# STM32MP157 register map
File version: 1.6
CPU: CM4 r0p1, little endian, no MPU, FPU, 4 interrupt priority bits
Registers are 32-bit, read-write, reset 0x0 unless marked. A register's access mark holds for its fields unless they carry their own. Offsets are from the block's base; [hi:lo] are bit positions; {n}, {i} and the like mark numbered series.

## TZC
Base 0x5C006000
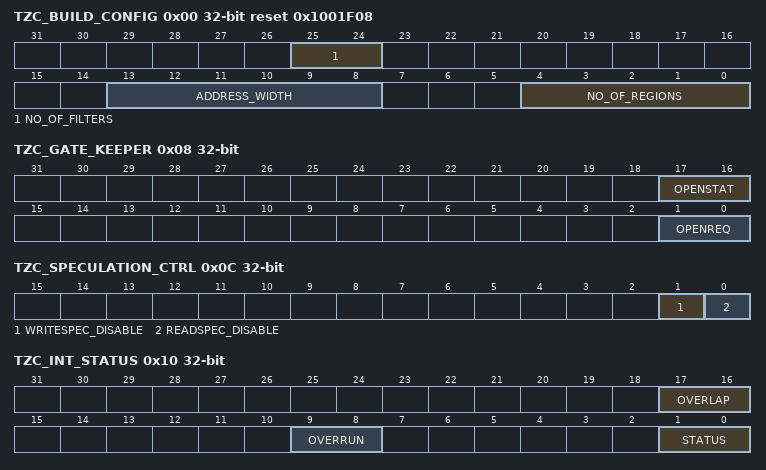
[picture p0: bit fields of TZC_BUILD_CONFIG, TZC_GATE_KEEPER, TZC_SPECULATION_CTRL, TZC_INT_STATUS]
0x00 TZC_BUILD_CONFIG ro reset 0x1001F08 — Provides information about TZC configuration.
  [25:24] NO_OF_FILTERS, [13:8] ADDRESS_WIDTH, [4:0] NO_OF_REGIONS
0x04 TZC_ACTION — Controls interrupt and bus error response behavior when regions permission failures occur.
  [1:0] REACTION_VALUE
0x08 TZC_GATE_KEEPER — Provides control and status for the gate keeper in each filter unit implemented.
  [17:16] OPENSTAT ro, [1:0] OPENREQ
0x0C TZC_SPECULATION_CTRL — Controls read and write access speculation.
  [1] WRITESPEC_DISABLE, [0] READSPEC_DISABLE
0x10 TZC_INT_STATUS ro — Contains the status of the interrupt signal, TZCINT, that reports access security violations or region overlap errors.
  [17:16] OVERLAP, [9:8] OVERRUN, [1:0] STATUS
0x14 TZC_INT_CLEAR — Interrupt clear for each filter.
  [1:0] CLEAR wo
0x20 TZC_FAIL_ADDRESS_LOW0 ro — Address low bits of the first failed access in the associated filter (0 to 1).
  [31:0] ADDR_STATUS_LOW
0x24 TZC_FAIL_ADDRESS_HIGH0 ro — Address high bit of the first failed access in the associated filter (0 to 1). Not used with 32bit address.
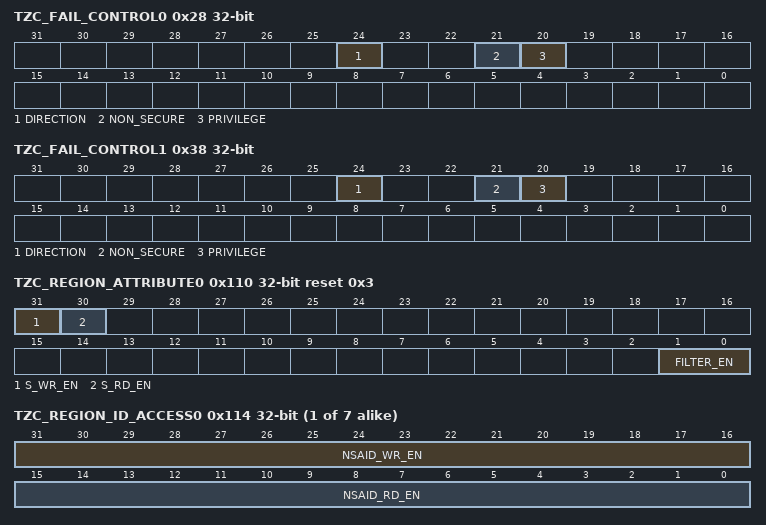
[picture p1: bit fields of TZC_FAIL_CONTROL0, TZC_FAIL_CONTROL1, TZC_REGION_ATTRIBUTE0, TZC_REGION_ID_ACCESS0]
0x28 TZC_FAIL_CONTROL0 ro — Status information about the first access that failed a region permission check in the associated filter (0 to 1).
  [24] DIRECTION, [21] NON_SECURE, [20] PRIVILEGE
0x2C TZC_FAIL_ID0 ro — Contains the master AXI ARID or AWID of the first access that failed a region permission check in the associated filter unit. This occurs even if the ACTION register is set to not drive the interrupt signal. AXI ID mapping is described in Table4: NSAID definition table (TBD).
  [10:0] ID
0x30 TZC_FAIL_ADDRESS_LOW1 ro — Address low bits of the first failed access in the associated filter (0 to 1).
  [31:0] ADDR_STATUS_LOW
0x34 TZC_FAIL_ADDRESS_HIGH1 ro — Address high bit of the first failed access in the associated filter (0 to 1). Not used with 32bit address.
0x38 TZC_FAIL_CONTROL1 ro — Status information about the first access that failed a region permission check in the associated filter (0 to 1).
  [24] DIRECTION, [21] NON_SECURE, [20] PRIVILEGE
0x3C TZC_FAIL_ID1 ro — Contains the master AXI ARID or AWID of the first access that failed a region permission check in the associated filter unit. This occurs even if the ACTION register is set to not drive the interrupt signal. AXI ID mapping is described in Table4: NSAID definition table (TBD).
  [10:0] ID
{0x104+0x20*i} TZC_REGION_BASE_HIGH{i} ro (i=0..6) — Base address high are not used with 32-bit address.
0x108 TZC_REGION_TOP_LOW0 ro reset 0xFFFFFFFF — Top address bits [31:12] for region 0.
  [31:12] TOP_ADDRESS_LOW
{0x10C+0x20*i} TZC_REGION_TOP_HIGH{i} ro (i=0..6) — Top address high of region are not used with 32-bit address.
0x110 TZC_REGION_ATTRIBUTE0 reset 0x3 — Region 0 attributes.
  [31] S_WR_EN, [30] S_RD_EN, [1:0] FILTER_EN ro
{0x114+0x20*i} TZC_REGION_ID_ACCESS{i} (i=0..6) — Region non-secure access based on NSAID.
  [31:16] NSAID_WR_EN, [15:0] NSAID_RD_EN
{0x100+0x20*i} TZC_REGION_BASE_LOW{i} (i=1..6) — Base address low for regions 1 to 8.
  [31:12] BASE_ADDRESS_LOW
{0x108+0x20*i} TZC_REGION_TOP_LOW{i} reset 0xFFF (i=1..7) — Top address bits [31:12] for region x.
  [31:12] TOP_ADDRESS_LOW
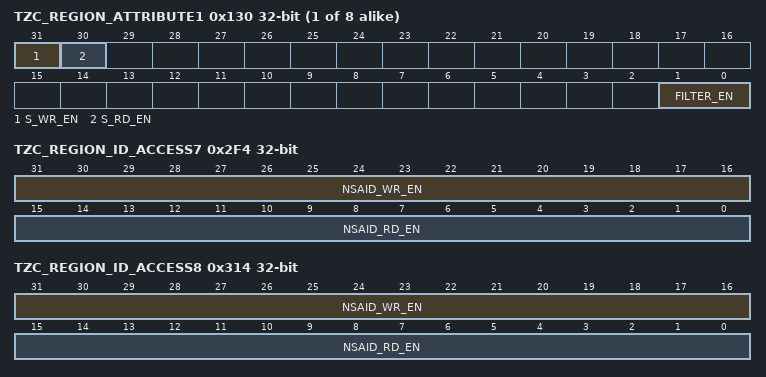
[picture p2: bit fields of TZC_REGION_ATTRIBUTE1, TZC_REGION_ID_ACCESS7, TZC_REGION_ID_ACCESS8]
{0x110+0x20*i} TZC_REGION_ATTRIBUTE{i} (i=1..8) — Region x attributes.
  [31] S_WR_EN, [30] S_RD_EN, [1:0] FILTER_EN
0x200 TZC_REGION_BASE_LOW8 — Base address low for regions 1 to 8.
  [31:12] BASE_ADDRESS_LOW
0x204 TZC_REGION_BASE_HIGH8 ro — Base address high are not used with 32-bit address.
0x2E0 TZC_REGION_BASE_LOW7 — Base address low for regions 1 to 8.
  [31:12] BASE_ADDRESS_LOW
0x2E4 TZC_REGION_BASE_HIGH7 ro — Base address high are not used with 32-bit address.
0x2EC TZC_REGION_TOP_HIGH7 ro — Top address high of region are not used with 32-bit address.
0x2F4 TZC_REGION_ID_ACCESS7 — Region non-secure access based on NSAID.
  [31:16] NSAID_WR_EN, [15:0] NSAID_RD_EN
0x308 TZC_REGION_TOP_LOW8 reset 0xFFF — Top address bits [31:12] for region x.
  [31:12] TOP_ADDRESS_LOW
0x30C TZC_REGION_TOP_HIGH8 ro — Top address high of region are not used with 32-bit address.
0x314 TZC_REGION_ID_ACCESS8 — Region non-secure access based on NSAID.
  [31:16] NSAID_WR_EN, [15:0] NSAID_RD_EN
0xFD0 TZC_PID4 ro reset 0x4 — Peripheral ID 4.
  [7:0] PER_ID_4
{0xFC0+4i} TZC_PID{i} ro (i=5..7) — Peripheral ID {i}.
  [7:0] PER_ID_{i}
0xFE0 TZC_PID0 ro reset 0x60 — Peripheral ID 0.
  [7:0] PER_ID_0
0xFE4 TZC_PID1 ro reset 0xB4 — Peripheral ID 1.
  [7:0] PER_ID_1
0xFE8 TZC_PID2 ro reset 0x2B — Peripheral ID 2.
  [7:0] PER_ID_2
0xFEC TZC_PID3 ro — Peripheral ID 3.
  [7:0] PER_ID_3
0xFF0 TZC_CID0 ro reset 0xD — Component ID 0.
  [7:0] COMP_ID_0
0xFF4 TZC_CID1 ro reset 0xF0 — Component ID 1.
  [7:0] COMP_ID_1
0xFF8 TZC_CID2 ro reset 0x5 — Component ID 2.
  [7:0] COMP_ID_2
0xFFC TZC_CID3 ro reset 0xB1 — Component ID 3.
  [7:0] COMP_ID_3
